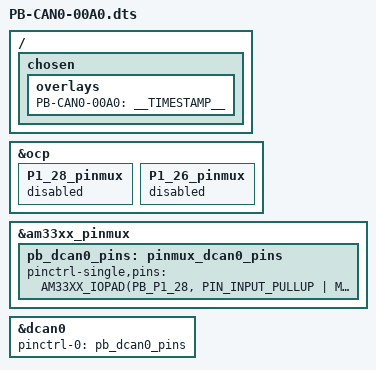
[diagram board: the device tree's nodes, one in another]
/*
 * Copyright (C) 2015 Robert Nelson <robertcnelson@gmail.com>
 *
 * Virtual cape for CAN0 on connector pins for P1.28 and P1.26 on PocketBeagle
 *
 * This program is free software; you can redistribute it and/or modify
 * it under the terms of the GNU General Public License version 2 as
 * published by the Free Software Foundation.
 */
/dts-v1/;
/plugin/;

#include <dt-bindings/pinctrl/am33xx.h>
#include <dt-bindings/board/am335x-pb-base.h>

/ {
	/*
	 * Helper to show loaded overlays under: /proc/device-tree/chosen/overlays/
	 */
	fragment@0 {
		target-path="/";
		__overlay__ {

			chosen {
				overlays {
					PB-CAN0-00A0 = __TIMESTAMP__;
				};
			};
		};
	};

	/*
	 * Free up the pins used by the cape from the pinmux helpers.
	 */
	fragment@1 {
		target = <&ocp>;
		__overlay__ {
			P1_28_pinmux { status = "disabled"; };	/* P1_28: i2c2_scl.d_can0_rx */
			P1_26_pinmux { status = "disabled"; };	/* P1_26: i2c2_sda.d_can0_tx */
		};
	};

	fragment@2 {
		target = <&am33xx_pinmux>;
		__overlay__ {
			pb_dcan0_pins: pinmux_dcan0_pins {
				/* https://github.com/beagleboard/BeagleBoard-DeviceTrees/blob/v4.19.x-ti/src/arm/am335x-pocketbeagle.dts#L320 */
				pinctrl-single,pins = <
					AM33XX_IOPAD(PB_P1_28, PIN_INPUT_PULLUP | MUX_MODE2)          /* uart1_rtsn.dcan0_rx */
					AM33XX_IOPAD(PB_P1_26, PIN_OUTPUT_PULLUP | MUX_MODE2)         /* uart1_ctsn.dcan0_tx */
				>;
			};
		};
	};

	fragment@3 {
		target = <&dcan0>;
		__overlay__ {
			status = "okay";
			pinctrl-names = "default";
			pinctrl-0 = <&pb_dcan0_pins>;
		};
	};
};
